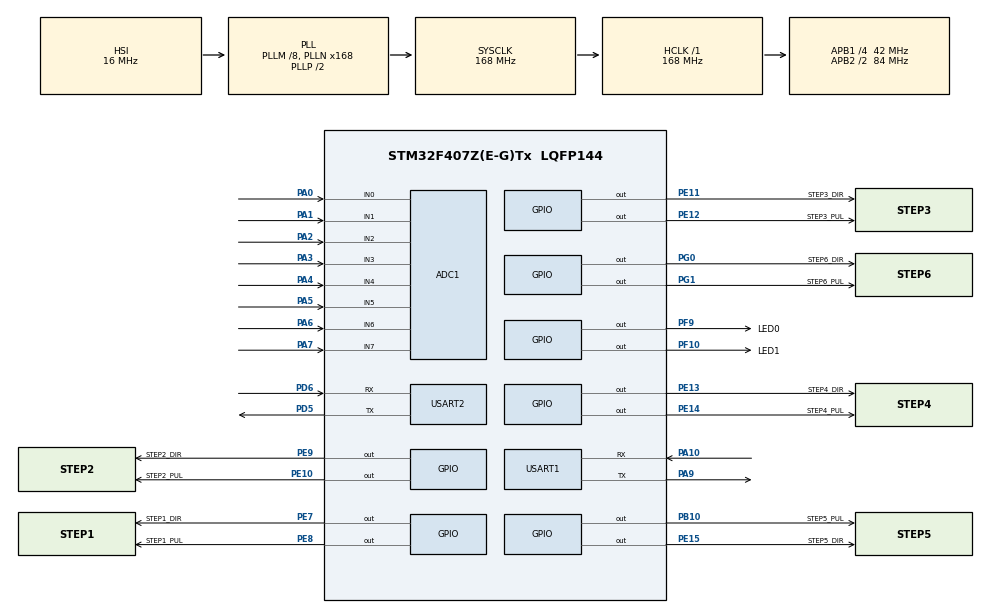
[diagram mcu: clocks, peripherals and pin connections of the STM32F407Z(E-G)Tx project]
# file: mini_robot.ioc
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Mcu.Family=STM32F4
Dma.USART2_RX.2.PeriphDataAlignment=DMA_PDATAALIGN_BYTE
PH0-OSC_IN.Signal=RCC_OSC_IN
RCC.CortexFreq_Value=168000000
Dma.USART1_TX.1.MemInc=DMA_MINC_ENABLE
ADC1.ContinuousConvMode=ENABLE
Dma.USART2_TX.3.MemInc=DMA_MINC_ENABLE
PE11.GPIO_Label=STEP3_DIR
SH.ADCx_IN2.0=ADC1_IN2,IN2
ADC1.SamplingTime-6\#ChannelRegularConversion=ADC_SAMPLETIME_56CYCLES
PG0.Signal=GPIO_Output
Dma.USART2_TX.3.Direction=DMA_MEMORY_TO_PERIPH
RCC.SYSCLKSource=RCC_SYSCLKSOURCE_PLLCLK
ProjectManager.StackSize=0x1600
VP_TIM1_VS_no_output1.Mode=Output Compare1 No Output
NVIC.ADC_IRQn=true\:5\:0\:false\:false\:true\:true\:true\:true
ADC1.Channel-5\#ChannelRegularConversion=ADC_CHANNEL_5
ADC1.Channel-3\#ChannelRegularConversion=ADC_CHANNEL_3
RCC.HCLKFreq_Value=168000000
SH.ADCx_IN3.0=ADC1_IN3,IN3
RCC.APB2TimFreq_Value=168000000
Dma.ADC1.0.Direction=DMA_PERIPH_TO_MEMORY
ADC1.Channel-2\#ChannelRegularConversion=ADC_CHANNEL_2
Dma.USART2_RX.2.Priority=DMA_PRIORITY_HIGH
Dma.USART2_RX.2.MemDataAlignment=DMA_MDATAALIGN_BYTE
NVIC.DMA2_Stream0_IRQn=true\:5\:0\:false\:false\:true\:true\:false\:true
Dma.ADC1.0.MemDataAlignment=DMA_MDATAALIGN_HALFWORD
PF10.GPIO_Label=LED1
RCC.AHBFreq_Value=168000000
PH0-OSC_IN.Mode=HSE-External-Oscillator
PD5.Mode=Asynchronous
ADC1.Channel-0\#ChannelRegularConversion=ADC_CHANNEL_0
RCC.HSE_VALUE=8000000
ADC1.ScanConvMode=ENABLE
ADC1.SamplingTime-4\#ChannelRegularConversion=ADC_SAMPLETIME_56CYCLES
ADC1.Channel-6\#ChannelRegularConversion=ADC_CHANNEL_6
ADC1.Rank-2\#ChannelRegularConversion=3
PE13.Signal=GPIO_Output
PC14-OSC32_IN.Mode=LSE-External-Oscillator
PE9.Signal=GPIO_Output
PA14.Mode=Serial_Wire
FREERTOS.HEAP_NUMBER=3
Dma.ADC1.0.PeriphInc=DMA_PINC_DISABLE
SH.ADCx_IN0.0=ADC1_IN0,IN0
VP_FREERTOS_VS_CMSIS_V1.Mode=CMSIS_V1
PE10.Signal=GPIO_Output
ADC1.SamplingTime-0\#ChannelRegularConversion=ADC_SAMPLETIME_56CYCLES
FREERTOS.configTOTAL_HEAP_SIZE=25360
Dma.USART1_TX.1.PeriphDataAlignment=DMA_PDATAALIGN_BYTE
PH1-OSC_OUT.Mode=HSE-External-Oscillator
Mcu.Package=LQFP144
PA6.Signal=ADCx_IN6
NVIC.DMA2_Stream7_IRQn=true\:5\:0\:false\:false\:true\:true\:false\:true
USART2.VirtualMode=VM_ASYNC
PA10.Signal=USART1_RX
PE12.GPIO_Label=STEP3_PUL
PG0.GPIO_Label=STEP6_DIR
Dma.USART2_RX.2.Direction=DMA_PERIPH_TO_MEMORY
RCC.APB2CLKDivider=RCC_HCLK_DIV2
SH.ADCx_IN1.0=ADC1_IN1,IN1
Dma.Request2=USART2_RX
Dma.Request1=USART1_TX
RCC.APB1TimFreq_Value=84000000
Dma.Request3=USART2_TX
Dma.ADC1.0.FIFOMode=DMA_FIFOMODE_DISABLE
Dma.USART1_TX.1.Priority=DMA_PRIORITY_LOW
PE7.Signal=GPIO_Output
NVIC.USART1_IRQn=true\:5\:0\:false\:false\:true\:true\:true\:true
PD6.Signal=USART2_RX
PE10.GPIO_Label=STEP2_PUL
ADC1.Rank-6\#ChannelRegularConversion=7
Dma.Request0=ADC1
NVIC.DMA1_Stream6_IRQn=true\:5\:0\:false\:false\:true\:true\:false\:true
ADC1.Rank-4\#ChannelRegularConversion=5
PA3.Signal=ADCx_IN3
Dma.USART1_TX.1.Direction=DMA_MEMORY_TO_PERIPH
PE14.GPIO_ModeDefaultOutputPP=GPIO_MODE_OUTPUT_OD
PC15-OSC32_OUT.Mode=LSE-External-Oscillator
Dma.USART2_TX.3.MemDataAlignment=DMA_MDATAALIGN_BYTE
Dma.USART1_TX.1.Instance=DMA2_Stream7
Dma.ADC1.0.Instance=DMA2_Stream0
FREERTOS.Tasks01=defaultTask,0,128,StartDefaultTask,Default,NULL,Dynamic,NULL,NULL;LedTask,-2,128,StartLedTask,Default,NULL,Dynamic,NULL,NULL;SendTask,0,512,StartSendTask,Default,NULL,Dynamic,NULL,NULL;RobotTask,2,256,StartRobotTask,Default,NULL,Dynamic,NULL,NULL;DemoTask,0,128,StartDemoTask,Default,NULL,Dynamic,NULL,NULL;TestTask,1,128,StartTestTask,Default,NULL,Dynamic,NULL,NULL;ModbusTask,0,512,StartModbusTask,Default,NULL,Dynamic,NULL,NULL
ADC1.Rank-0\#ChannelRegularConversion=1
ADC1.Channel-4\#ChannelRegularConversion=ADC_CHANNEL_4
PA10.Mode=Asynchronous
Dma.USART2_TX.3.Instance=DMA1_Stream6
SH.ADCx_IN6.0=ADC1_IN6,IN6
PG1.Signal=GPIO_Output
TIM1.Channel-Output\ Compare1\ No\ Output=TIM_CHANNEL_1
PE14.GPIO_Label=STEP4_PUL
PD5.Signal=USART2_TX
Dma.USART2_TX.3.PeriphInc=DMA_PINC_DISABLE
RCC.APB1CLKDivider=RCC_HCLK_DIV4
PC14-OSC32_IN.Signal=RCC_OSC32_IN
PD6.Mode=Asynchronous
NVIC.USART2_IRQn=true\:5\:0\:false\:false\:true\:true\:true\:true
ADC1.SamplingTime-2\#ChannelRegularConversion=ADC_SAMPLETIME_56CYCLES
Dma.USART2_RX.2.Mode=DMA_CIRCULAR
PA0-WKUP.Signal=ADCx_IN0
ADC1.Channel-7\#ChannelRegularConversion=ADC_CHANNEL_7
PA13.Signal=SYS_JTMS-SWDIO
Dma.ADC1.0.PeriphDataAlignment=DMA_PDATAALIGN_HALFWORD
PA9.Mode=Asynchronous
PE15.GPIO_Label=STEP5_DIR
Dma.USART2_RX.2.MemInc=DMA_MINC_ENABLE
ProjectManager.TargetToolchain=STM32CubeIDE
PB10.GPIO_Label=STEP5_PUL
NVIC.DMA1_Stream5_IRQn=true\:5\:0\:false\:false\:true\:true\:false\:true
SH.ADCx_IN7.0=ADC1_IN7,IN7
Dma.ADC1.0.Mode=DMA_CIRCULAR
PE8.GPIO_Label=STEP1_PUL
Dma.ADC1.0.Priority=DMA_PRIORITY_HIGH
PA9.Signal=USART1_TX
ADC1.Channel-1\#ChannelRegularConversion=ADC_CHANNEL_1
Dma.USART2_TX.3.PeriphDataAlignment=DMA_PDATAALIGN_BYTE
Dma.USART1_TX.1.FIFOMode=DMA_FIFOMODE_DISABLE
PF9.GPIO_Label=LED0
PE11.Signal=GPIO_Output
PC15-OSC32_OUT.Signal=RCC_OSC32_OUT
PE9.GPIO_Label=STEP2_DIR
PA1.Signal=ADCx_IN1
PB10.Signal=GPIO_Output
PA5.Signal=ADCx_IN5
Dma.USART2_TX.3.FIFOMode=DMA_FIFOMODE_DISABLE
Dma.USART1_TX.1.MemDataAlignment=DMA_MDATAALIGN_BYTE
board=custom
RCC.VCOOutputFreq_Value=336000000
PG1.GPIO_Label=STEP6_PUL
Dma.USART2_RX.2.PeriphInc=DMA_PINC_DISABLE
RCC.APB2Freq_Value=84000000
PE14.Signal=GPIO_Output
PE15.Signal=GPIO_Output
PE8.Signal=GPIO_Output
PF10.Signal=GPIO_Output
Dma.USART2_TX.3.Mode=DMA_NORMAL
PH1-OSC_OUT.Signal=RCC_OSC_OUT
SH.ADCx_IN4.0=ADC1_IN4,IN4
ADC1.DMAContinuousRequests=ENABLE
ADC1.NbrOfConversion=8
PA13.Mode=Serial_Wire
Mcu.Name=STM32F407Z(E-G)Tx
PE7.GPIO_Label=STEP1_DIR
PE12.Signal=GPIO_Output
PA2.Signal=ADCx_IN2
NVIC.TIM1_CC_IRQn=true\:5\:0\:false\:false\:true\:true\:true\:true
RCC.48MHZClocksFreq_Value=84000000
PA4.Signal=ADCx_IN4
ADC1.SamplingTime-1\#ChannelRegularConversion=ADC_SAMPLETIME_56CYCLES
RCC.SYSCLKFreq_VALUE=168000000
ADC1.master=1
PE13.GPIO_Label=STEP4_DIR
ADC1.Rank-3\#ChannelRegularConversion=4
ADC1.SamplingTime-3\#ChannelRegularConversion=ADC_SAMPLETIME_56CYCLES
Dma.USART2_RX.2.Instance=DMA1_Stream5
PE13.GPIO_ModeDefaultOutputPP=GPIO_MODE_OUTPUT_OD
Dma.USART1_TX.1.Mode=DMA_NORMAL
USART1.VirtualMode=VM_ASYNC
ADC1.Rank-1\#ChannelRegularConversion=2
PA14.Signal=SYS_JTCK-SWCLK
Dma.ADC1.0.MemInc=DMA_MINC_ENABLE
ProjectManager.HeapSize=0x800
Dma.USART1_TX.1.PeriphInc=DMA_PINC_DISABLE
ADC1.SamplingTime-5\#ChannelRegularConversion=ADC_SAMPLETIME_56CYCLES
PF9.Signal=GPIO_Output
RCC.HSI_VALUE=16000000
Dma.USART2_TX.3.Priority=DMA_PRIORITY_HIGH
SH.ADCx_IN5.0=ADC1_IN5,IN5
ADC1.Rank-7\#ChannelRegularConversion=8
NVIC.PriorityGroup=NVIC_PRIORITYGROUP_4
ADC1.NbrOfConversionFlag=1
RCC.PLLM=8
RCC.PLLN=168
Dma.USART2_RX.2.FIFOMode=DMA_FIFOMODE_DISABLE
ADC1.SamplingTime-7\#ChannelRegularConversion=ADC_SAMPLETIME_56CYCLES
RCC.APB1Freq_Value=42000000
ADC1.Rank-5\#ChannelRegularConversion=6
PA7.Signal=ADCx_IN7

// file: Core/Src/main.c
/* USER CODE BEGIN Header */
/**
  ******************************************************************************
  * @file           : main.c
  * @brief          : Main program body
  ******************************************************************************
  * @attention
  *
  * <h2><center>&copy; Copyright (c) 2021 STMicroelectronics.
  * All rights reserved.</center></h2>
  *
  * This software component is licensed by ST under BSD 3-Clause license,
  * the "License"; You may not use this file except in compliance with the
  * License. You may obtain a copy of the License at:
  *                        opensource.org/licenses/BSD-3-Clause
  *
  ******************************************************************************
  */
/* USER CODE END Header */
#include "main.h"
#include "cmsis_os.h"
#include "adc.h"
#include "dma.h"
#include "tim.h"
#include "usart.h"
#include "gpio.h"

/* USER CODE BEGIN Includes */
#include "math.h"
/* USER CODE END Includes */

void SystemClock_Config(void);
void MX_FREERTOS_Init(void);

int main(void)
{

  /* MCU Configuration--------------------------------------------------------*/

  /* Reset of all peripherals, Initializes the Flash interface and the Systick. */
  HAL_Init();

  /* Configure the system clock */
  SystemClock_Config();

  /* Initialize all configured peripherals */
  MX_GPIO_Init();
  MX_DMA_Init();
  MX_ADC1_Init();
  MX_USART1_UART_Init();
  MX_USART2_UART_Init();
  MX_TIM1_Init();
  /* USER CODE BEGIN 2 */
  HAL_ADC_Start_DMA(&hadc1, (uint32_t *)adc_data, 8);
  HAL_UART_Receive_DMA(&huart2, rx_data, rx_bufSize);
  HAL_TIM_Base_Start_IT(&htim1);
  HAL_TIM_OC_Start_IT(&htim1,TIM_CHANNEL_1);

  /* USER CODE END 2 */

  /* Call init function for freertos objects (in freertos.c) */
  MX_FREERTOS_Init();
  /* Start scheduler */
  osKernelStart();

  /* We should never get here as control is now taken by the scheduler */
  /* Infinite loop */
  while (1)
  {

  }
}

void SystemClock_Config(void)
{
  RCC_OscInitTypeDef RCC_OscInitStruct = {0};
  RCC_ClkInitTypeDef RCC_ClkInitStruct = {0};

  /** Configure the main internal regulator output voltage
  */
  __HAL_RCC_PWR_CLK_ENABLE();
  __HAL_PWR_VOLTAGESCALING_CONFIG(PWR_REGULATOR_VOLTAGE_SCALE1);
  /** Initializes the RCC Oscillators according to the specified parameters
  * in the RCC_OscInitTypeDef structure.
  */
  RCC_OscInitStruct.OscillatorType = RCC_OSCILLATORTYPE_HSI;
  RCC_OscInitStruct.HSIState = RCC_HSI_ON;
  RCC_OscInitStruct.HSICalibrationValue = RCC_HSICALIBRATION_DEFAULT;
  RCC_OscInitStruct.PLL.PLLState = RCC_PLL_ON;
  RCC_OscInitStruct.PLL.PLLSource = RCC_PLLSOURCE_HSI;
  RCC_OscInitStruct.PLL.PLLM = 8;
  RCC_OscInitStruct.PLL.PLLN = 168;
  RCC_OscInitStruct.PLL.PLLP = RCC_PLLP_DIV2;
  RCC_OscInitStruct.PLL.PLLQ = 4;
  if (HAL_RCC_OscConfig(&RCC_OscInitStruct) != HAL_OK)
  {
    Error_Handler();
  }
  /** Initializes the CPU, AHB and APB buses clocks
  */
  RCC_ClkInitStruct.ClockType = RCC_CLOCKTYPE_HCLK|RCC_CLOCKTYPE_SYSCLK
                              |RCC_CLOCKTYPE_PCLK1|RCC_CLOCKTYPE_PCLK2;
  RCC_ClkInitStruct.SYSCLKSource = RCC_SYSCLKSOURCE_PLLCLK;
  RCC_ClkInitStruct.AHBCLKDivider = RCC_SYSCLK_DIV1;
  RCC_ClkInitStruct.APB1CLKDivider = RCC_HCLK_DIV4;
  RCC_ClkInitStruct.APB2CLKDivider = RCC_HCLK_DIV2;

  if (HAL_RCC_ClockConfig(&RCC_ClkInitStruct, FLASH_LATENCY_5) != HAL_OK)
  {
    Error_Handler();
  }
}

/* USER CODE BEGIN 4 */

int get_max(int *arr){
	int max=0;
	for(int i=3;i<9;i++){
		if(arr[i]>max)max=arr[i];
	}
	return max;
}
int max(int a, int b){
	if(a>b)return a;
	else return b;
}

int max_pulse=0;
int step1_err=0;
int step2_err=0;
int step3_err=0;
int step4_err=0;
int step5_err=0;
int step6_err=0;

int step1_foc=0;
int step2_foc=0;
int step3_foc=0;
int step4_foc=0;
int step5_foc=0;
int step6_foc=0;

float step1_scale=0;
float step2_scale=0;
float step3_scale=0;
float step4_scale=0;
float step5_scale=0;
float step6_scale=0;

char step1_flag=0;
char step2_flag=0;
char step3_flag=0;
char step4_flag=0;
char step5_flag=0;
char step6_flag=0;

long cur_num = 0;
int acc_pulse = 0;
int instruct_speed = 0;
char step4_is_run = 0;

double x=0,y=0,z=0,a1=0,a2=0,a3=0;
double L1=2520,L2=1410,L3=0;

double ik_a1=0,ik_a2=0,ik_a3=0,ik_a4=0,ik_a5=0,ik_a6=0;
double new_x=0,new_y=0,new_z=0,ik_x,ik_y,ik_z;
int num =0;
int max_xyz=0;
int last_xyz=0;
char key_flag = 0;
char max_flag = 0;
int start_pul1,start_pul2,start_pul3,start_pul4,start_pul5,start_pul6;
void HAL_TIM_OC_DelayElapsedCallback(TIM_HandleTypeDef *htim)
{
	if(htim==&htim1){

		HAL_GPIO_WritePin(STEP1_PUL_GPIO_Port,STEP1_PUL_Pin,GPIO_PIN_SET);
		HAL_GPIO_WritePin(STEP2_PUL_GPIO_Port,STEP2_PUL_Pin,GPIO_PIN_SET);
		HAL_GPIO_WritePin(STEP3_PUL_GPIO_Port,STEP3_PUL_Pin,GPIO_PIN_SET);
		HAL_GPIO_WritePin(STEP4_PUL_GPIO_Port,STEP4_PUL_Pin,GPIO_PIN_RESET);
		HAL_GPIO_WritePin(STEP5_PUL_GPIO_Port,STEP5_PUL_Pin,GPIO_PIN_SET);
		HAL_GPIO_WritePin(STEP6_PUL_GPIO_Port,STEP6_PUL_Pin,GPIO_PIN_SET);

//		num++;
//		if(num%10==0)
//		{
//			L3 = sqrt(-2.0*L1*L2*cos((cur_pulse3*0.0113924+180)/57.2958)+L1*L1+L2*L2);
//			float cc = cur_pulse2*0.0067164/57.2958 - acos((L1*L1+L3*L3-L2*L2)/(2.0*L1*L3));
//			z = L3*sin(cc);
//			instruct[4][0] = (int)z;
//			x = cos(cur_pulse1*0.006338/57.2958)*L3*cos(cc);
//			y = sin(cur_pulse1*0.006338/57.2958)*L3*cos(cc);
//			instruct[4][1] = (int)x;
//			instruct[4][2] = (int)y;
//		}

		if(!is_start){
			if(foc_cut[0]>100){
				step1_foc++;
				if(step1_foc>(10000/(foc_cut[0]))){
					step1_foc=0;
					HAL_GPIO_WritePin(STEP1_DIR_GPIO_Port,STEP1_DIR_Pin,GPIO_PIN_RESET);
					HAL_GPIO_WritePin(STEP1_PUL_GPIO_Port,STEP1_PUL_Pin,GPIO_PIN_RESET);
					cur_pulse1++;
				}
			}

			if(foc_cut[0]<-100){
				step1_foc--;
				if(step1_foc<(10000/(foc_cut[0]))){
					step1_foc=0;
					HAL_GPIO_WritePin(STEP1_DIR_GPIO_Port,STEP1_DIR_Pin,GPIO_PIN_SET);
					HAL_GPIO_WritePin(STEP1_PUL_GPIO_Port,STEP1_PUL_Pin,GPIO_PIN_RESET);
					cur_pulse1--;
				}
			}

			if(foc_cut[1]>100){
				step2_foc++;
				if(step2_foc>(20000/(foc_cut[1]))){
					step2_foc=0;
					HAL_GPIO_WritePin(STEP2_DIR_GPIO_Port,STEP2_DIR_Pin,GPIO_PIN_RESET);
					HAL_GPIO_WritePin(STEP2_PUL_GPIO_Port,STEP2_PUL_Pin,GPIO_PIN_RESET);
					cur_pulse2++;
				}
			}

			if(foc_cut[1]<-100){
				step2_foc--;
				if(step2_foc<(20000/(foc_cut[1]))){
					step2_foc=0;
					HAL_GPIO_WritePin(STEP2_DIR_GPIO_Port,STEP2_DIR_Pin,GPIO_PIN_SET);
					HAL_GPIO_WritePin(STEP2_PUL_GPIO_Port,STEP2_PUL_Pin,GPIO_PIN_RESET);
					cur_pulse2--;
				}
			}

			if(foc_cut[2]>100){
				step3_foc++;
				if(step3_foc>(10000/(foc_cut[2]))){
					step3_foc=0;
					HAL_GPIO_WritePin(STEP3_DIR_GPIO_Port,STEP3_DIR_Pin,GPIO_PIN_SET);
					HAL_GPIO_WritePin(STEP3_PUL_GPIO_Port,STEP3_PUL_Pin,GPIO_PIN_RESET);
					cur_pulse3++;
				}
			}

			if(foc_cut[2]<-100){
				step3_foc--;
				if(step3_foc<(10000/(foc_cut[2]))){
					step3_foc=0;
					HAL_GPIO_WritePin(STEP3_DIR_GPIO_Port,STEP3_DIR_Pin,GPIO_PIN_RESET);
					HAL_GPIO_WritePin(STEP3_PUL_GPIO_Port,STEP3_PUL_Pin,GPIO_PIN_RESET);
					cur_pulse3--;
				}
			}

			if(foc_cut[3]>100){
				step4_foc++;
				if(step4_foc>(10000/(foc_cut[3]))){
					step4_foc=0;
					HAL_GPIO_WritePin(STEP4_DIR_GPIO_Port,STEP4_DIR_Pin,GPIO_PIN_RESET);
					HAL_GPIO_WritePin(STEP4_PUL_GPIO_Port,STEP4_PUL_Pin,GPIO_PIN_SET);
					cur_pulse4++;
					HAL_GPIO_WritePin(STEP5_DIR_GPIO_Port,STEP5_DIR_Pin,GPIO_PIN_SET);
					HAL_GPIO_WritePin(STEP5_PUL_GPIO_Port,STEP5_PUL_Pin,GPIO_PIN_RESET);

				}
			}

			if(foc_cut[3]<-100){
				step4_foc--;
				if(step4_foc<(10000/(foc_cut[3]))){
					step4_foc=0;
					HAL_GPIO_WritePin(STEP4_DIR_GPIO_Port,STEP4_DIR_Pin,GPIO_PIN_SET);
					HAL_GPIO_WritePin(STEP4_PUL_GPIO_Port,STEP4_PUL_Pin,GPIO_PIN_SET);
					cur_pulse4--;
					HAL_GPIO_WritePin(STEP5_DIR_GPIO_Port,STEP5_DIR_Pin,GPIO_PIN_RESET);
					HAL_GPIO_WritePin(STEP5_PUL_GPIO_Port,STEP5_PUL_Pin,GPIO_PIN_RESET);
				}
			}

			if(foc_cut[4]>100){
				step5_foc++;
				if(step5_foc>(10000/(foc_cut[4]))){
					step5_foc=0;
					HAL_GPIO_WritePin(STEP5_DIR_GPIO_Port,STEP5_DIR_Pin,GPIO_PIN_RESET);
					HAL_GPIO_WritePin(STEP5_PUL_GPIO_Port,STEP5_PUL_Pin,GPIO_PIN_RESET);
					cur_pulse5++;
				}
			}

			if(foc_cut[4]<-100){
				step5_foc--;
				if(step5_foc<(10000/(foc_cut[4]))){
					step5_foc=0;
					HAL_GPIO_WritePin(STEP5_DIR_GPIO_Port,STEP5_DIR_Pin,GPIO_PIN_SET);
					HAL_GPIO_WritePin(STEP5_PUL_GPIO_Port,STEP5_PUL_Pin,GPIO_PIN_RESET);
					cur_pulse5--;
				}
			}

			if(foc_cut[5]>100){
				step6_foc++;
				if(step6_foc>(5000/(foc_cut[5]))){
					step6_foc=0;
					HAL_GPIO_WritePin(STEP6_DIR_GPIO_Port,STEP6_DIR_Pin,GPIO_PIN_SET);
					HAL_GPIO_WritePin(STEP6_PUL_GPIO_Port,STEP6_PUL_Pin,GPIO_PIN_RESET);
					cur_pulse6=cur_pulse6+6;
				}
			}

			if(foc_cut[5]<-100){
				step6_foc--;
				if(step6_foc<(5000/(foc_cut[5]))){
					step6_foc=0;
					HAL_GPIO_WritePin(STEP6_DIR_GPIO_Port,STEP6_DIR_Pin,GPIO_PIN_RESET);
					HAL_GPIO_WritePin(STEP6_PUL_GPIO_Port,STEP6_PUL_Pin,GPIO_PIN_RESET);
					cur_pulse6=cur_pulse6-6;
				}
			}

		}

		if((is_start||is_single_run))
		{
			step_time++;
			instruct[0][10] = (int)step_time/100.0;
//			if(max_pulse==(int)step)
			if(((abs(cur_pulse1-instruct[instruct_step][4])<10)&&
				 (abs(cur_pulse2-instruct[instruct_step][5])<10)&&
				 (abs(cur_pulse3-instruct[instruct_step][6])<10))||
				 (key_flag==0&&is_single_run))
			{
				if(!is_single_run&&(int)(step_time/100.0)>instruct[instruct_step][10])
				{
					step_time = 0;
					instruct_step++;instruct[2][2]++;
					key_flag = 0;
				}
				step=0;
				if((instruct[2][2]+10)>instruct[2][1])
				{
					instruct[2][2] = 0;
					instruct_step=10;

					if((instruct[3][4]*65536+instruct[3][3])>=(instruct[3][2]*65536+instruct[3][1]))
					{
						is_start = 0;
						instruct[3][0]=0;
					}
					else{
						cur_num = instruct[3][4]*65536+instruct[3][3];
						cur_num++;
						instruct[3][4] = cur_num>>16;
						instruct[3][3] = cur_num&0xffff;

					}
				}

				max_pulse = max(abs(instruct[instruct_step][4]-cur_pulse1),abs(instruct[instruct_step][5]-cur_pulse2));
				max_pulse = max(max_pulse,abs(instruct[instruct_step][6]-cur_pulse3));
				max_pulse = max(max_pulse,abs(instruct[instruct_step][7]-cur_pulse4));
				max_pulse = max(max_pulse,abs(instruct[instruct_step][8]-cur_pulse5));
				max_pulse = max(max_pulse,abs(instruct[instruct_step][9]-cur_pulse6));
				step1_scale=abs(instruct[instruct_step][4]-cur_pulse1)/(float)max_pulse;
				step2_scale=abs(instruct[instruct_step][5]-cur_pulse2)/(float)max_pulse;
				step3_scale=abs(instruct[instruct_step][6]-cur_pulse3)/(float)max_pulse;
				step4_scale=abs(instruct[instruct_step][7]-cur_pulse4)/(float)max_pulse;
				step5_scale=abs(instruct[instruct_step][8]-cur_pulse5)/(float)max_pulse;
				step6_scale=abs(instruct[instruct_step][9]-cur_pulse6)/(float)max_pulse;

//				if(     abs(instruct[instruct_step][4]-cur_pulse1)==max_pulse)max_flag = 1;
//				else if(abs(instruct[instruct_step][5]-cur_pulse2)==max_pulse)max_flag = 2;
//				else if(abs(instruct[instruct_step][6]-cur_pulse3)==max_pulse)max_flag = 3;
//				else if(abs(instruct[instruct_step][7]-cur_pulse4)==max_pulse)max_flag = 4;
//				else if(abs(instruct[instruct_step][8]-cur_pulse5)==max_pulse)max_flag = 5;
//				else if(abs(instruct[instruct_step][9]-cur_pulse6)==max_pulse)max_flag = 6;

//				step_speed = 0;
//				instruct_speed = (int)instruct[instruct_step][2]*instruct[3][5]/100.0;
			}
			instruct_speed = (int)instruct[instruct_step][2]*instruct[3][5]/100.0;
			if(instruct[instruct_step][0]==0)
			{

				if((key_flag==0&&is_single_run)||(key_flag==0&&is_start))
				{
					step_speed = 0;
					step=0;
					max_pulse = max(abs(instruct[instruct_step][4]-cur_pulse1),abs(instruct[instruct_step][5]-cur_pulse2));
					max_pulse = max(max_pulse,abs(instruct[instruct_step][6]-cur_pulse3));
					max_pulse = max(max_pulse,abs(instruct[instruct_step][7]-cur_pulse4));
					max_pulse = max(max_pulse,abs(instruct[instruct_step][8]-cur_pulse5));
					max_pulse = max(max_pulse,abs(instruct[instruct_step][9]-cur_pulse6));
					step1_scale=abs(instruct[instruct_step][4]-cur_pulse1)/(float)max_pulse;
					step2_scale=abs(instruct[instruct_step][5]-cur_pulse2)/(float)max_pulse;
					step3_scale=abs(instruct[instruct_step][6]-cur_pulse3)/(float)max_pulse;
					step4_scale=abs(instruct[instruct_step][7]-cur_pulse4)/(float)max_pulse;
					step5_scale=abs(instruct[instruct_step][8]-cur_pulse5)/(float)max_pulse;
					step6_scale=abs(instruct[instruct_step][9]-cur_pulse6)/(float)max_pulse;

					key_flag=1;

				}
				instruct[0][2] = (int)step_speed;
				instruct[0][3] = (int)((step_acc)*((instruct_speed)*1.1-step_speed)/instruct_speed);
				if((int)step_speed<(instruct_speed)&&((float)step<((float)max_pulse/2.0)))
				{
					step_acc = instruct[instruct_step][3];
	//				step_speed=step_speed+(step_acc/1000.0)*(1-sin(((instruct[instruct_step][2])-step_speed)/162.4));
					step_speed=step_speed+(step_acc/1000.0)*((instruct_speed)*1.1-step_speed)/instruct_speed;
					acc_pulse = (int)step;
				}

				if((int)step_speed>(instruct_speed)||(((int)step)>(max_pulse-acc_pulse)&&(int)step_speed>2))
				{
					step_acc = instruct[instruct_step][3];
	//				step_speed=step_speed-(step_acc/1000.0)*(1-sin((step_speed-(instruct[instruct_step][2]))/162.4));
					step_speed=step_speed-(step_acc/1000.0)*((instruct_speed)*1.1-step_speed)/instruct_speed;
				}

				step=step+step_speed/255.0;

				if((step1_err!=(int)(step*step1_scale))&&(abs(foc_cut[0])<800)){
					step1_err=(int)(step*step1_scale);
					if(cur_pulse1<instruct[instruct_step][4]){
						HAL_GPIO_WritePin(STEP1_DIR_GPIO_Port,STEP1_DIR_Pin,GPIO_PIN_RESET);
						HAL_GPIO_WritePin(STEP1_PUL_GPIO_Port,STEP1_PUL_Pin,GPIO_PIN_RESET);
						cur_pulse1++;

					}
					else if (cur_pulse1>instruct[instruct_step][4]){
						HAL_GPIO_WritePin(STEP1_DIR_GPIO_Port,STEP1_DIR_Pin,GPIO_PIN_SET);
						HAL_GPIO_WritePin(STEP1_PUL_GPIO_Port,STEP1_PUL_Pin,GPIO_PIN_RESET);
						cur_pulse1--;

					}

				}

				if((step2_err!=(int)(step*step2_scale))&&(abs(foc_cut[1])<800)){
					step2_err=(int)(step*step2_scale);
					if(cur_pulse2<instruct[instruct_step][5]){
						HAL_GPIO_WritePin(STEP2_DIR_GPIO_Port,STEP2_DIR_Pin,GPIO_PIN_RESET);
						HAL_GPIO_WritePin(STEP2_PUL_GPIO_Port,STEP2_PUL_Pin,GPIO_PIN_RESET);
						cur_pulse2++;

					}
					else if (cur_pulse2>instruct[instruct_step][5]){
						HAL_GPIO_WritePin(STEP2_DIR_GPIO_Port,STEP2_DIR_Pin,GPIO_PIN_SET);
						HAL_GPIO_WritePin(STEP2_PUL_GPIO_Port,STEP2_PUL_Pin,GPIO_PIN_RESET);
						cur_pulse2--;

					}

				}

				if((step3_err!=(int)(step*step3_scale))&&(abs(foc_cut[2])<800)){
					step3_err=(int)(step*step3_scale);
					if(cur_pulse3<instruct[instruct_step][6]){
						HAL_GPIO_WritePin(STEP3_DIR_GPIO_Port,STEP3_DIR_Pin,GPIO_PIN_SET);
						HAL_GPIO_WritePin(STEP3_PUL_GPIO_Port,STEP3_PUL_Pin,GPIO_PIN_RESET);
						cur_pulse3++;

					}
					else if (cur_pulse3>instruct[instruct_step][6]){
						HAL_GPIO_WritePin(STEP3_DIR_GPIO_Port,STEP3_DIR_Pin,GPIO_PIN_RESET);
						HAL_GPIO_WritePin(STEP3_PUL_GPIO_Port,STEP3_PUL_Pin,GPIO_PIN_RESET);
						cur_pulse3--;

					}

				}

				if((step4_err!=(int)(step*step4_scale))&&(abs(foc_cut[3])<800)){

					step4_err=(int)(step*step4_scale);
					if(cur_pulse4<instruct[instruct_step][7]){
						step4_is_run = 1;
						HAL_GPIO_WritePin(STEP4_DIR_GPIO_Port,STEP4_DIR_Pin,GPIO_PIN_RESET);
						HAL_GPIO_WritePin(STEP4_PUL_GPIO_Port,STEP4_PUL_Pin,GPIO_PIN_SET);
						cur_pulse4++;
						HAL_GPIO_WritePin(STEP5_DIR_GPIO_Port,STEP5_DIR_Pin,GPIO_PIN_SET);
						HAL_GPIO_WritePin(STEP5_PUL_GPIO_Port,STEP5_PUL_Pin,GPIO_PIN_RESET);

					}
					else if (cur_pulse4>instruct[instruct_step][7]){
						step4_is_run = 1;
						HAL_GPIO_WritePin(STEP4_DIR_GPIO_Port,STEP4_DIR_Pin,GPIO_PIN_SET);
						HAL_GPIO_WritePin(STEP4_PUL_GPIO_Port,STEP4_PUL_Pin,GPIO_PIN_SET);
						cur_pulse4--;
						HAL_GPIO_WritePin(STEP5_DIR_GPIO_Port,STEP5_DIR_Pin,GPIO_PIN_RESET);
						HAL_GPIO_WritePin(STEP5_PUL_GPIO_Port,STEP5_PUL_Pin,GPIO_PIN_RESET);

					}

				}else step4_is_run=0;

				if((step5_err!=(int)(step*step5_scale))&&(step4_is_run==0)&&(abs(foc_cut[4])<800)){
					step5_err=(int)(step*step5_scale);
					if(cur_pulse5<instruct[instruct_step][8]){
						HAL_GPIO_WritePin(STEP5_DIR_GPIO_Port,STEP5_DIR_Pin,GPIO_PIN_RESET);
						HAL_GPIO_WritePin(STEP5_PUL_GPIO_Port,STEP5_PUL_Pin,GPIO_PIN_RESET);
						cur_pulse5++;
					}
					else if (cur_pulse5>instruct[instruct_step][8]){
						HAL_GPIO_WritePin(STEP5_DIR_GPIO_Port,STEP5_DIR_Pin,GPIO_PIN_SET);
						HAL_GPIO_WritePin(STEP5_PUL_GPIO_Port,STEP5_PUL_Pin,GPIO_PIN_RESET);
						cur_pulse5--;
					}

				}

				if((step6_err!=(int)(step*step6_scale))&&(abs(foc_cut[5])<800)){
					step6_err=(int)(step*step6_scale);
					if(cur_pulse6<instruct[instruct_step][9]){
						HAL_GPIO_WritePin(STEP6_DIR_GPIO_Port,STEP6_DIR_Pin,GPIO_PIN_SET);
						HAL_GPIO_WritePin(STEP6_PUL_GPIO_Port,STEP6_PUL_Pin,GPIO_PIN_RESET);
						cur_pulse6=cur_pulse6+6;
					}
					else if (cur_pulse6>instruct[instruct_step][9]){
						HAL_GPIO_WritePin(STEP6_DIR_GPIO_Port,STEP6_DIR_Pin,GPIO_PIN_RESET);
						HAL_GPIO_WritePin(STEP6_PUL_GPIO_Port,STEP6_PUL_Pin,GPIO_PIN_RESET);
						cur_pulse6=cur_pulse6-6;
					}
				}

			}

			if(instruct[instruct_step][0]==1)
			{

				if((key_flag==0&&is_single_run)||(key_flag==0&&is_start))
				{
					key_flag = 1;
					start_pul1 = cur_pulse1;
					start_pul2 = cur_pulse2;
					start_pul3 = cur_pulse3;
					start_pul4 = cur_pulse4;
					start_pul5 = cur_pulse5;
					start_pul6 = cur_pulse6;

					L3 = sqrt(-2.0*L1*L2*cos((cur_pulse3*0.0113924+180)/57.2958)+L1*L1+L2*L2);
					float cc = cur_pulse2*0.0067164/57.2958 - acos((L1*L1+L3*L3-L2*L2)/(2.0*L1*L3));
					z = L3*sin(cc);
					x = cos(cur_pulse1*0.006338/57.2958)*L3*cos(cc);
					y = sin(cur_pulse1*0.006338/57.2958)*L3*cos(cc);
					new_x = x;
					new_y = y;
					new_z = z;

					double ik_L3 = sqrt(-2.0*L1*L2*cos((instruct[instruct_step][6]*0.0113924+180)/57.2958)+L1*L1+L2*L2);
					double ccc = instruct[instruct_step][5]*0.0067164/57.2958 - acos((L1*L1+ik_L3*ik_L3-L2*L2)/(2.0*L1*ik_L3));
					ik_z = ik_L3*sin(ccc);
					ik_x = cos(instruct[instruct_step][4]*0.006338/57.2958)*ik_L3*cos(ccc);
					ik_y = sin(instruct[instruct_step][4]*0.006338/57.2958)*ik_L3*cos(ccc);
					max_xyz = max(abs((int)ik_z-(int)z),abs((int)ik_y-(int)y));
					max_xyz = max(max_xyz,abs((int)ik_x-(int)x));
					if(max_xyz>3)
					{
						new_z = new_z+(ik_z-z)*2.0/(float)max_xyz;
						new_x = new_x+(ik_x-x)*2.0/(float)max_xyz;
						new_y = new_y+(ik_y-y)*2.0/(float)max_xyz;
						instruct[4][0] = (int)ik_z;
						instruct[4][1] = (int)ik_x;
						instruct[4][2] = (int)ik_y;

						instruct[4][8] = (int)new_z;
						instruct[4][9] = (int)new_x;
						instruct[4][10] = (int)new_y;

						double new_L3 = sqrt(new_z*new_z+new_x*new_x+new_y*new_y);
						ik_a1 = atan2(new_y,new_x)*57.2958/0.006338;
						ik_a2 = (atan2(new_z,sqrt(new_x*new_x+new_y*new_y))+acos((L1*L1+new_L3*new_L3-L2*L2)/(2*L1*new_L3)))*57.2958/0.0067164;
						ik_a3 = acos((L1*L1-new_L3*new_L3+L2*L2)/(2*L1*L2))*57.2958/0.0113924;
						ik_a4 = -(-90.0/0.0156673 + (atan2(sqrt(new_x*new_x+new_y*new_y),new_z)+
								acos((L2*L2+new_L3*new_L3-L1*L1)/(2*L2*new_L3)))*57.2958/0.0156673)*4.0/90.0;

						instruct[4][3] = (int)(ik_a1*0.006338);
						instruct[4][4] = (int)(ik_a2*0.0067164);
						instruct[4][5] = (int)(ik_a3*0.0113924);
						instruct[4][6] = (int)(ik_a4*0.0156673);

						max_pulse = max(abs((int)ik_a1-cur_pulse1),abs((int)ik_a2-cur_pulse2));
						max_pulse = max(max_pulse,abs((int)(ik_a3-180.0/0.0113924)-cur_pulse3));
	//					max_pulse = max(max_pulse,abs(instruct[instruct_step][7]-cur_pulse4));
	//					max_pulse = max(max_pulse,abs(instruct[instruct_step][8]-cur_pulse5));
	//					max_pulse = max(max_pulse,abs(instruct[instruct_step][9]-cur_pulse6));
						step1_scale=abs((int)ik_a1-cur_pulse1)/(float)max_pulse;
						step2_scale=abs((int)ik_a2-cur_pulse2)/(float)max_pulse;
						step3_scale=abs((int)(ik_a3-180.0/0.0113924)-cur_pulse3)/(float)max_pulse;
//						step4_scale=abs((int)(ik_a4)-cur_pulse4)/(float)max_pulse;
	//					step5_scale=abs(instruct[instruct_step][8]-cur_pulse5)/(float)max_pulse;
	//					step6_scale=abs(instruct[instruct_step][9]-cur_pulse6)/(float)max_pulse;

						step_acc = instruct[instruct_step][3];
						float distance_start =(sqrt(
								(cur_pulse1-start_pul1)*(cur_pulse1-start_pul1)+
								(cur_pulse2-start_pul2)*(cur_pulse2-start_pul2)+
								(cur_pulse3-start_pul3)*(cur_pulse3-start_pul3)));
						float distance_all =(sqrt(
								(start_pul1-instruct[instruct_step][4])*(start_pul1-instruct[instruct_step][4])+
								(start_pul2-instruct[instruct_step][5])*(start_pul2-instruct[instruct_step][5])+
								(start_pul3-instruct[instruct_step][6])*(start_pul3-instruct[instruct_step][6])));
						float speed_start = distance_start*sqrt((step_acc/100.0)*instruct[3][5]/5000.0)+3;
						if(((int)(speed_start)<instruct_speed)&&((int)(distance_start)<(int)(distance_all/2.0)))
						{
							step_speed = speed_start;
						}

						float distance_end =(sqrt(
								(cur_pulse1-instruct[instruct_step][4])*(cur_pulse1-instruct[instruct_step][4])+
								(cur_pulse2-instruct[instruct_step][5])*(cur_pulse2-instruct[instruct_step][5])+
								(cur_pulse3-instruct[instruct_step][6])*(cur_pulse3-instruct[instruct_step][6])));
						float speed_end = distance_end*sqrt((step_acc/100.0)*instruct[3][5]/5000.0)+3;
						if(((int)(speed_end)<instruct_speed)&&((int)(distance_end)<(int)(distance_all/2.0)))
						{
							step_speed = speed_end;
						}

					}
				}

				if((abs(((int)ik_a1)-cur_pulse1)<3)&&
					(abs(((int)ik_a2)-cur_pulse2)<3)&&
					(abs(((int)(ik_a3-180/0.0113924))-cur_pulse3)<3)&&
					((abs((int)ik_z-(int)new_z)>1)||
					(abs((int)ik_x-(int)new_x)>1)||
					(abs((int)ik_y-(int)new_y)>1)))
				{

					new_z = new_z+(ik_z-z)*2.0/(float)max_xyz;
					new_x = new_x+(ik_x-x)*2.0/(float)max_xyz;
					new_y = new_y+(ik_y-y)*2.0/(float)max_xyz;
					instruct[4][0] = (int)ik_z;
					instruct[4][1] = (int)ik_x;
					instruct[4][2] = (int)ik_y;

					instruct[4][8] = (int)new_z;
					instruct[4][9] = (int)new_x;
					instruct[4][10] = (int)new_y;

					double new_L3 = sqrt(new_z*new_z+new_x*new_x+new_y*new_y);
					ik_a1 = atan2(new_y,new_x)*57.2958/0.006338;
					ik_a2 = (atan2(new_z,sqrt(new_x*new_x+new_y*new_y))+acos((L1*L1+new_L3*new_L3-L2*L2)/(2.0*L1*new_L3)))*57.2958/0.0067164;
					ik_a3 = acos((L1*L1-new_L3*new_L3+L2*L2)/(2.0*L1*L2))*57.2958/0.0113924;
					ik_a4 = -(-90.0/0.0156673 + (atan2(sqrt(new_x*new_x+new_y*new_y),new_z)+
							acos((L2*L2+new_L3*new_L3-L1*L1)/(2.0*L2*new_L3)))*57.2958/0.0156673)*4.0/90.0;

					instruct[4][3] = (int)(ik_a1*0.006338);
					instruct[4][4] = (int)(ik_a2*0.0067164);
					instruct[4][5] = (int)(ik_a3*0.0113924);
					instruct[4][6] = (int)(ik_a4*0.0156673);
					instruct[4][7] = (int)new_L3;

					max_pulse = max(abs((int)ik_a1-cur_pulse1),abs((int)ik_a2-cur_pulse2));
					max_pulse = max(max_pulse,abs((int)(ik_a3-180.0/0.0113924)-cur_pulse3));
//					max_pulse = max(max_pulse,abs(instruct[instruct_step][7]-cur_pulse4));
//					max_pulse = max(max_pulse,abs(instruct[instruct_step][8]-cur_pulse5));
//					max_pulse = max(max_pulse,abs(instruct[instruct_step][9]-cur_pulse6));
					step1_scale=abs((int)ik_a1-cur_pulse1)/(float)max_pulse;
					step2_scale=abs((int)ik_a2-cur_pulse2)/(float)max_pulse;
					step3_scale=abs((int)(ik_a3-180.0/0.0113924)-cur_pulse3)/(float)max_pulse;
//					step4_scale=abs((int)(ik_a4)-cur_pulse4)/(float)max_pulse;
//					step4_scale=abs(instruct[instruct_step][7]-cur_pulse4)/(float)max_pulse;
//					step5_scale=abs(instruct[instruct_step][8]-cur_pulse5)/(float)max_pulse;
//					step6_scale=abs(instruct[instruct_step][9]-cur_pulse6)/(float)max_pulse;
					step_acc = instruct[instruct_step][3];
					float distance_start =(sqrt(
							(cur_pulse1-start_pul1)*(cur_pulse1-start_pul1)+
							(cur_pulse2-start_pul2)*(cur_pulse2-start_pul2)+
							(cur_pulse3-start_pul3)*(cur_pulse3-start_pul3)));
					float distance_all =(sqrt(
							(start_pul1-instruct[instruct_step][4])*(start_pul1-instruct[instruct_step][4])+
							(start_pul2-instruct[instruct_step][5])*(start_pul2-instruct[instruct_step][5])+
							(start_pul3-instruct[instruct_step][6])*(start_pul3-instruct[instruct_step][6])));
					float speed_start = distance_start*sqrt((step_acc/100.0)*instruct[3][5]/5000.0)+3;
					if(((int)(speed_start)<instruct_speed)&&((int)(distance_start)<(int)(distance_all/2.0)))
					{
						step_speed = speed_start;
					}

					float distance_end =(sqrt(
							(cur_pulse1-instruct[instruct_step][4])*(cur_pulse1-instruct[instruct_step][4])+
							(cur_pulse2-instruct[instruct_step][5])*(cur_pulse2-instruct[instruct_step][5])+
							(cur_pulse3-instruct[instruct_step][6])*(cur_pulse3-instruct[instruct_step][6])));
					float speed_end = distance_end*sqrt((step_acc/100.0)*instruct[3][5]/5000.0)+3;
					if(((int)(speed_end)<instruct_speed)&&((int)(distance_end)<(int)(distance_all/2.0)))
					{
						step_speed = speed_end;
					}

				}

//				if((abs((int)ik_z-(int)new_z)<1)&&
//						(abs((int)ik_x-(int)new_x)<1)&&
//						(abs((int)ik_y-(int)new_y)<1))
//				{
//					ik_a1 = instruct[instruct_step][4];
//					ik_a2 = instruct[instruct_step][5];
//					ik_a3 = instruct[instruct_step][7];
//
//				}

				instruct[0][2] = (int)step_speed;
				instruct[0][3] = (int)(((step_acc)*instruct[3][5]/100.0));
				step=step+step_speed/255.0;

				if((step1_err!=(int)(step*step1_scale))&&(abs(foc_cut[0])<800)){
					step1_err=(int)(step*step1_scale);
					if(cur_pulse1<(int)ik_a1){
						HAL_GPIO_WritePin(STEP1_DIR_GPIO_Port,STEP1_DIR_Pin,GPIO_PIN_RESET);
						HAL_GPIO_WritePin(STEP1_PUL_GPIO_Port,STEP1_PUL_Pin,GPIO_PIN_RESET);
						cur_pulse1++;

					}
					else if (cur_pulse1>(int)ik_a1){
						HAL_GPIO_WritePin(STEP1_DIR_GPIO_Port,STEP1_DIR_Pin,GPIO_PIN_SET);
						HAL_GPIO_WritePin(STEP1_PUL_GPIO_Port,STEP1_PUL_Pin,GPIO_PIN_RESET);
						cur_pulse1--;

					}

				}

				if((step2_err!=(int)(step*step2_scale))&&(abs(foc_cut[1])<800)){
					step2_err=(int)(step*step2_scale);
					if(cur_pulse2<(int)ik_a2){
						HAL_GPIO_WritePin(STEP2_DIR_GPIO_Port,STEP2_DIR_Pin,GPIO_PIN_RESET);
						HAL_GPIO_WritePin(STEP2_PUL_GPIO_Port,STEP2_PUL_Pin,GPIO_PIN_RESET);
						cur_pulse2++;

					}
					else if (cur_pulse2>(int)ik_a2){
						HAL_GPIO_WritePin(STEP2_DIR_GPIO_Port,STEP2_DIR_Pin,GPIO_PIN_SET);
						HAL_GPIO_WritePin(STEP2_PUL_GPIO_Port,STEP2_PUL_Pin,GPIO_PIN_RESET);
						cur_pulse2--;

					}

				}

				if((step3_err!=(int)(step*step3_scale))&&(abs(foc_cut[2])<800))
				{
					step3_err=(int)(step*step3_scale);
					if(cur_pulse3<(int)(ik_a3-180.0/0.0113924))
					{
						HAL_GPIO_WritePin(STEP3_DIR_GPIO_Port,STEP3_DIR_Pin,GPIO_PIN_SET);
						HAL_GPIO_WritePin(STEP3_PUL_GPIO_Port,STEP3_PUL_Pin,GPIO_PIN_RESET);
						cur_pulse3++;

					}
					else if (cur_pulse3>(int)(ik_a3-180.0/0.0113924))
					{
						HAL_GPIO_WritePin(STEP3_DIR_GPIO_Port,STEP3_DIR_Pin,GPIO_PIN_RESET);
						HAL_GPIO_WritePin(STEP3_PUL_GPIO_Port,STEP3_PUL_Pin,GPIO_PIN_RESET);
						cur_pulse3--;

					}

				}

				if((step4_err!=(int)(step*step4_scale))&&(abs(foc_cut[3])<800))
				{
					step4_err=(int)(step*step4_scale);
//					if(cur_pulse4<(int)(ik_a4))
					if(cur_pulse4<instruct[instruct_step][7])
					{
						step4_is_run = 1;
						HAL_GPIO_WritePin(STEP4_DIR_GPIO_Port,STEP4_DIR_Pin,GPIO_PIN_RESET);
						HAL_GPIO_WritePin(STEP4_PUL_GPIO_Port,STEP4_PUL_Pin,GPIO_PIN_SET);
						cur_pulse4++;
						HAL_GPIO_WritePin(STEP5_DIR_GPIO_Port,STEP5_DIR_Pin,GPIO_PIN_SET);
						HAL_GPIO_WritePin(STEP5_PUL_GPIO_Port,STEP5_PUL_Pin,GPIO_PIN_RESET);

					}
//					else if(cur_pulse4>(int)(ik_a4))
					else if (cur_pulse4>instruct[instruct_step][7])
					{
						step4_is_run = 1;
						HAL_GPIO_WritePin(STEP4_DIR_GPIO_Port,STEP4_DIR_Pin,GPIO_PIN_SET);
						HAL_GPIO_WritePin(STEP4_PUL_GPIO_Port,STEP4_PUL_Pin,GPIO_PIN_SET);
						cur_pulse4--;
						HAL_GPIO_WritePin(STEP5_DIR_GPIO_Port,STEP5_DIR_Pin,GPIO_PIN_RESET);
						HAL_GPIO_WritePin(STEP5_PUL_GPIO_Port,STEP5_PUL_Pin,GPIO_PIN_RESET);

					}

				}else step4_is_run=0;

				if((step5_err!=(int)(step*step5_scale))&&(step4_is_run==0)&&(abs(foc_cut[4])<800)){
					step5_err=(int)(step*step5_scale);
					if(cur_pulse5<instruct[instruct_step][8]){
						HAL_GPIO_WritePin(STEP5_DIR_GPIO_Port,STEP5_DIR_Pin,GPIO_PIN_RESET);
						HAL_GPIO_WritePin(STEP5_PUL_GPIO_Port,STEP5_PUL_Pin,GPIO_PIN_RESET);
						cur_pulse5++;
					}
					else if (cur_pulse5>instruct[instruct_step][8]){
						HAL_GPIO_WritePin(STEP5_DIR_GPIO_Port,STEP5_DIR_Pin,GPIO_PIN_SET);
						HAL_GPIO_WritePin(STEP5_PUL_GPIO_Port,STEP5_PUL_Pin,GPIO_PIN_RESET);
						cur_pulse5--;
					}

				}

				if((step6_err!=(int)(step*step6_scale))&&(abs(foc_cut[5])<800)){
					step6_err=(int)(step*step6_scale);
					if(cur_pulse6<instruct[instruct_step][9]){
						HAL_GPIO_WritePin(STEP6_DIR_GPIO_Port,STEP6_DIR_Pin,GPIO_PIN_SET);
						HAL_GPIO_WritePin(STEP6_PUL_GPIO_Port,STEP6_PUL_Pin,GPIO_PIN_RESET);
						cur_pulse6=cur_pulse6+6;
					}
					else if (cur_pulse6>instruct[instruct_step][9]){
						HAL_GPIO_WritePin(STEP6_DIR_GPIO_Port,STEP6_DIR_Pin,GPIO_PIN_RESET);
						HAL_GPIO_WritePin(STEP6_PUL_GPIO_Port,STEP6_PUL_Pin,GPIO_PIN_RESET);
						cur_pulse6=cur_pulse6-6;
					}
				}

			}

		}else key_flag = 0;

	}

}

/* USER CODE END 4 */

void Error_Handler(void)
{
  __disable_irq();
  while (1)
  {
  }
}

/************************ (C) COPYRIGHT STMicroelectronics *****END OF FILE****/

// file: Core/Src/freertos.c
/* USER CODE BEGIN Header */
/**
  ******************************************************************************
  * File Name          : freertos.c
  * Description        : Code for freertos applications
  ******************************************************************************
  * @attention
  *
  * <h2><center>&copy; Copyright (c) 2021 STMicroelectronics.
  * All rights reserved.</center></h2>
  *
  * This software component is licensed by ST under Ultimate Liberty license
  * SLA0044, the "License"; You may not use this file except in compliance with
  * the License. You may obtain a copy of the License at:
  *                             www.st.com/SLA0044
  *
  ******************************************************************************
  */
/* USER CODE END Header */

#include "FreeRTOS.h"
#include "task.h"
#include "main.h"
#include "cmsis_os.h"

/* USER CODE BEGIN Includes */
#include "adc.h"
#include "dma.h"
#include "tim.h"
#include "usart.h"
#include "gpio.h"
/* USER CODE END Includes */

/* USER CODE BEGIN PD */
#define FLASH_USER_START_ADDR   ADDR_FLASH_SECTOR_5   /* Start @ of user Flash area */
#define FLASH_USER_END_ADDR     ADDR_FLASH_SECTOR_6  +  GetSectorSize(ADDR_FLASH_SECTOR_6) -1 /* End @ of user Flash area : sector start address + sector size -1 */

#define DATA_32                 ((uint32_t)0)

uint32_t FirstSector = 0, NbOfSectors = 0, Address = 0;
uint32_t SectorError = 0;
__IO uint32_t data32 = 0 , MemoryProgramStatus = 0;

static FLASH_EraseInitTypeDef EraseInitStruct;

static uint32_t GetSector(uint32_t Address);
static uint32_t GetSectorSize(uint32_t Sector);

/**
  * @brief  Gets the sector of a given address
  * @param  None
  * @retval The sector of a given address
  */
static uint32_t GetSector(uint32_t Address)
{
  uint32_t sector = 0;

  if((Address < ADDR_FLASH_SECTOR_1) && (Address >= ADDR_FLASH_SECTOR_0))
  {
    sector = FLASH_SECTOR_0;
  }
  else if((Address < ADDR_FLASH_SECTOR_2) && (Address >= ADDR_FLASH_SECTOR_1))
  {
    sector = FLASH_SECTOR_1;
  }
  else if((Address < ADDR_FLASH_SECTOR_3) && (Address >= ADDR_FLASH_SECTOR_2))
  {
    sector = FLASH_SECTOR_2;
  }
  else if((Address < ADDR_FLASH_SECTOR_4) && (Address >= ADDR_FLASH_SECTOR_3))
  {
    sector = FLASH_SECTOR_3;
  }
  else if((Address < ADDR_FLASH_SECTOR_5) && (Address >= ADDR_FLASH_SECTOR_4))
  {
    sector = FLASH_SECTOR_4;
  }
  else if((Address < ADDR_FLASH_SECTOR_6) && (Address >= ADDR_FLASH_SECTOR_5))
  {
    sector = FLASH_SECTOR_5;
  }
  else if((Address < ADDR_FLASH_SECTOR_7) && (Address >= ADDR_FLASH_SECTOR_6))
  {
    sector = FLASH_SECTOR_6;
  }
  else if((Address < ADDR_FLASH_SECTOR_8) && (Address >= ADDR_FLASH_SECTOR_7))
  {
    sector = FLASH_SECTOR_7;
  }
  else if((Address < ADDR_FLASH_SECTOR_9) && (Address >= ADDR_FLASH_SECTOR_8))
  {
    sector = FLASH_SECTOR_8;
  }
  else if((Address < ADDR_FLASH_SECTOR_10) && (Address >= ADDR_FLASH_SECTOR_9))
  {
    sector = FLASH_SECTOR_9;
  }
  else if((Address < ADDR_FLASH_SECTOR_11) && (Address >= ADDR_FLASH_SECTOR_10))
  {
    sector = FLASH_SECTOR_10;
  }
  else /* (Address < FLASH_END_ADDR) && (Address >= ADDR_FLASH_SECTOR_11) */
  {
    sector = FLASH_SECTOR_11;
  }

  return sector;
}

/**
  * @brief  Gets sector Size
  * @param  None
  * @retval The size of a given sector
  */
static uint32_t GetSectorSize(uint32_t Sector)
{
  uint32_t sectorsize = 0x00;

  if((Sector == FLASH_SECTOR_0) || (Sector == FLASH_SECTOR_1) || (Sector == FLASH_SECTOR_2) || (Sector == FLASH_SECTOR_3))
  {
    sectorsize = 16 * 1024;
  }
  else if(Sector == FLASH_SECTOR_4)
  {
    sectorsize = 64 * 1024;
  }
  else
  {
    sectorsize = 128 * 1024;
  }
  return sectorsize;
}

/* USER CODE END PD */

/* USER CODE BEGIN Variables */

uint32_t count=0;
uint16_t adc_filter[11];
uint16_t adc_first[11];
int adc_one[11];
int foc[6];

int foc_cut[6];
int16_t instruct[500][11]=
{{0,0,0,0,0,0,0,0,0,0,0},
{0,0,0,0,0,0,0,0,0,0,0},
{0,0,0,0,0,0,0,0,0,0,0},
{0,0,0,0,0,0,0,0,0,0,0},
{0,0,0,0,0,0,0,0,0,0,0},
{0,0,0,0,0,0,0,0,0,0,0},
{0,0,0,0,0,0,0,0,0,0,0},
{0,0,0,0,0,0,0,0,0,0,0},
{0,0,0,0,0,0,0,0,0,0,0},
{0,0,0,0,0,0,0,0,0,0,0},
{0,0,0x3f,0x3f,0,0,0,0,0,0,0},
{0,0,0x3f,0x3f,500,0,0,0,0,0,0},
{0,0,0x1f,0x3f,600,0,0,0,0,0,0},
{0,0,0x3f,0x3f,600,500,0,0,0,0,0},
{0,0,0x1f,0x3f,600,600,0,0,0,0,0},
{0,0,0x3f,0x3f,600,600,500,0,0,0,0},
{0,0,0x1f,0x3f,600,600,600,0,0,0,0},
{0,0,0x3f,0x3f,0,0,0,0,0,0,0},
{0,0,0x1f,0x3f,0,0,0,0,0,0,0},
{0,0,0x3f,0x3f,0,0,0,0,0,0,0},
{0,0,0x1f,0x3f,0,0,0,0,0,0,0},
{0,0,0x3f,0x3f,0,0,0,0,0,0,0},
{0,0,0x1f,0x3f,0,0,0,0,0,0,0},
{0,0,0x2f,0x3f,0,0,0,0,0,0,0},
{0,0,0x1f,0x3f,0,0,0,0,0,0,0},
{0,0,0x0f,0x3f,0,0,0,0,0,0,0}};//模式，条件|输出，速度，加速度，位置，时间延时

int instruct_step=10;
int total_step =500;
float step=0;
float step_speed=0;
float step_acc=0;
float step_time=0;
char is_start=0;
char is_stop=0;
char is_single_run=0;
char is_record=0;
//电机1参数
int tar_pulse1=0;
int cur_pulse1=0;
int pre_pulse1=0;
int tar_speed1=0;
int cur_speed1=0;
int tar_acc1=0;
int cur_acc1=0;

//电机2参数
int tar_pulse2=0;
int cur_pulse2=0;
int pre_pulse2=0;
int tar_speed2=0;
int cur_speed2=0;
int tar_acc2=0;
int cur_acc2=0;

//电机3参数
int tar_pulse3=0;
int cur_pulse3=0;
int tar_speed3=0;
int cur_speed3=0;
int tar_acc3=0;
int cur_acc3=0;

//电机4参数
int tar_pulse4=0;
int cur_pulse4=0;
int tar_speed4=0;
int cur_speed4=0;
int tar_acc4=0;
int cur_acc4=0;

//电机5参数
int tar_pulse5=0;
int cur_pulse5=0;
int tar_speed5=0;
int cur_speed5=0;
int tar_acc5=0;
int cur_acc5=0;

//电机6参数
int tar_pulse6=0;
int cur_pulse6=0;
int tar_speed6=0;
int cur_speed6=0;
int tar_acc6=0;
int cur_acc6=0;

unsigned short CRC16_Modbus ( unsigned char *pdata, int len)
{
	unsigned short crc=0xFFFF;
	int i, j;
	for ( j=0; j<len;j++)
	{
		crc=crc^pdata[j];
		for ( i=0; i<8; i++)
		{
			if( ( crc&0x0001) >0)
			{
				crc=crc>>1;
				crc=crc^ 0xa001;
			}
			else
				crc=crc>>1;
		}
	}
	return crc;
}

/* USER CODE END Variables */
osThreadId defaultTaskHandle;
osThreadId LedTaskHandle;
osThreadId SendTaskHandle;
osThreadId RobotTaskHandle;
osThreadId DemoTaskHandle;
osThreadId TestTaskHandle;
osThreadId ModbusTaskHandle;

void StartDefaultTask(void const * argument);
void StartLedTask(void const * argument);
void StartSendTask(void const * argument);
void StartRobotTask(void const * argument);
void StartDemoTask(void const * argument);
void StartTestTask(void const * argument);
void StartModbusTask(void const * argument);

void MX_FREERTOS_Init(void); /* (MISRA C 2004 rule 8.1) */

/* GetIdleTaskMemory prototype (linked to static allocation support) */
void vApplicationGetIdleTaskMemory( StaticTask_t **ppxIdleTaskTCBBuffer, StackType_t **ppxIdleTaskStackBuffer, uint32_t *pulIdleTaskStackSize );

/* USER CODE BEGIN GET_IDLE_TASK_MEMORY */
static StaticTask_t xIdleTaskTCBBuffer;
static StackType_t xIdleStack[configMINIMAL_STACK_SIZE];

void vApplicationGetIdleTaskMemory( StaticTask_t **ppxIdleTaskTCBBuffer, StackType_t **ppxIdleTaskStackBuffer, uint32_t *pulIdleTaskStackSize )
{
  *ppxIdleTaskTCBBuffer = &xIdleTaskTCBBuffer;
  *ppxIdleTaskStackBuffer = &xIdleStack[0];
  *pulIdleTaskStackSize = configMINIMAL_STACK_SIZE;
  /* place for user code */
}
/* USER CODE END GET_IDLE_TASK_MEMORY */

void MX_FREERTOS_Init(void) {

  /* Create the thread(s) */
  /* definition and creation of defaultTask */
  osThreadDef(defaultTask, StartDefaultTask, osPriorityNormal, 0, 128);
  defaultTaskHandle = osThreadCreate(osThread(defaultTask), NULL);

  /* definition and creation of LedTask */
  osThreadDef(LedTask, StartLedTask, osPriorityNormal, 0, 128);
  LedTaskHandle = osThreadCreate(osThread(LedTask), NULL);

  /* definition and creation of SendTask */
  osThreadDef(SendTask, StartSendTask, osPriorityNormal, 0, 512);
  SendTaskHandle = osThreadCreate(osThread(SendTask), NULL);

  /* definition and creation of RobotTask */
  osThreadDef(RobotTask, StartRobotTask, osPriorityNormal, 0, 256);
  RobotTaskHandle = osThreadCreate(osThread(RobotTask), NULL);

  /* definition and creation of DemoTask */
  osThreadDef(DemoTask, StartDemoTask, osPriorityNormal, 0, 128);
  DemoTaskHandle = osThreadCreate(osThread(DemoTask), NULL);

  /* definition and creation of TestTask */
  osThreadDef(TestTask, StartTestTask, osPriorityIdle, 0, 128);
  TestTaskHandle = osThreadCreate(osThread(TestTask), NULL);

  /* definition and creation of ModbusTask */
  osThreadDef(ModbusTask, StartModbusTask, osPriorityNormal, 0, 512);
  ModbusTaskHandle = osThreadCreate(osThread(ModbusTask), NULL);

}

void StartDefaultTask(void const * argument)
{
  for(;;)
  {
    osDelay(1);
  }
}

void StartLedTask(void const * argument)
{
  /* USER CODE BEGIN StartLedTask */

  /* Infinite loop */
  for(;;)
  {
  	HAL_GPIO_TogglePin(LED0_GPIO_Port, LED0_Pin);
//  	HAL_GPIO_TogglePin(STEP4_PUL_GPIO_Port, STEP4_PUL_Pin);
    osDelay(100);
  }
  /* USER CODE END StartLedTask */
}

void StartSendTask(void const * argument)
{
  /* USER CODE BEGIN StartSendTask */
  /* Infinite loop */
  for(;;)
  {

  	instruct[0][4] = cur_pulse1*0.6338;
  	instruct[0][5] = cur_pulse2*0.67164;
  	instruct[0][6] = cur_pulse3*1.13924;
  	instruct[0][7] = cur_pulse4*1.56673;
  	instruct[0][8] = cur_pulse5*2.45108;
  	instruct[0][9] = cur_pulse6;

  	instruct[2][4] = (instruct[2][2]+10)*11;
  	instruct_step = instruct[2][2]+10;
  	total_step = instruct[2][1];
    osDelay(10);
  }
  /* USER CODE END StartSendTask */
}

void StartRobotTask(void const * argument)
{
  /* USER CODE BEGIN StartRobotTask */
	osDelay(1000);

	Address = FLASH_USER_START_ADDR;
	for(int j=11;j<(500*11);j++)
	{
		instruct[j/11][j%11] = (*(__IO int16_t*)Address);
		Address = Address + 2;
	}
	instruct[1][0]=0;
	instruct[1][1]=0;
	instruct[1][2]=0;
	instruct[1][3]=0;
	instruct[1][4]=0;
	instruct[1][5]=0;
	instruct[1][6]=0;
	instruct[1][7]=0;
	instruct[1][8]=0;
	instruct[1][9]=0;
	instruct[1][10]=0;
	instruct[2][0]=0;
	instruct[2][2]=0;

	is_start = 0;
  /* Infinite loop */
  for(;;)
  {
  	if(is_start==0)
  	{
  		if(instruct[0][0]==0)
  		{
  			for(int i=0;i<6;i++)
  			{
  				if(foc_cut[i]>-10)foc_cut[i]-=10;
  				if(foc_cut[i]<10)foc_cut[i]+=10;
  			}
  		}
  		else if(instruct[0][0]==1&&foc_cut[0]<3000)foc_cut[0]++;
  		else if(instruct[0][0]==2&&foc_cut[0]>-3000)foc_cut[0]--;
  		else if(instruct[0][0]==4&&foc_cut[1]<3000)foc_cut[1]++;
  		else if(instruct[0][0]==8&&foc_cut[1]>-3000)foc_cut[1]--;
  		else if(instruct[0][0]==16&&foc_cut[2]<3000)foc_cut[2]++;
  		else if(instruct[0][0]==32&&foc_cut[2]>-3000)foc_cut[2]--;
  		else if(instruct[0][0]==64&&foc_cut[3]<3000)foc_cut[3]++;
  		else if(instruct[0][0]==128&&foc_cut[3]>-3000)foc_cut[3]--;
  		else if(instruct[0][0]==256&&foc_cut[4]<3000)foc_cut[4]++;
  		else if(instruct[0][0]==512&&foc_cut[4]>-3000)foc_cut[4]--;
  		else if(instruct[0][0]==1024&&foc_cut[5]<3000)foc_cut[5]++;
  		else if(instruct[0][0]==2048&&foc_cut[5]>-3000)foc_cut[5]--;

  		if(instruct[2][0]==0)
  		{
  			is_single_run = 0;
  		}
  		else if(instruct[2][0]==1)
  		{

  			instruct[instruct_step][4] = cur_pulse1;
  			instruct[instruct_step][5] = cur_pulse2;
  			instruct[instruct_step][6] = cur_pulse3;
  			instruct[instruct_step][7] = cur_pulse4;
  			instruct[instruct_step][8] = cur_pulse5;
  			instruct[instruct_step][9] = cur_pulse6;
  		}
  		else if(instruct[2][0]==2)
  		{
  			is_single_run = 1;
  		}

  		else if(instruct[2][0]==4)
  		{
  		  /* Unlock the Flash to enable the flash control register access *************/
  		  HAL_FLASH_Unlock();

  		  /* Erase the user Flash area
  		    (area defined by FLASH_USER_START_ADDR and FLASH_USER_END_ADDR) ***********/

  		  /* Get the 1st sector to erase */
  		  FirstSector = GetSector(FLASH_USER_START_ADDR);
  		  /* Get the number of sector to erase from 1st sector*/
  		  NbOfSectors = GetSector(FLASH_USER_END_ADDR) - FirstSector + 1;

  		  /* Fill EraseInit structure*/
  		  EraseInitStruct.TypeErase = FLASH_TYPEERASE_SECTORS;
  		  EraseInitStruct.VoltageRange = FLASH_VOLTAGE_RANGE_3;
  		  EraseInitStruct.Sector = FirstSector;
  		  EraseInitStruct.NbSectors = NbOfSectors;
  		  if(HAL_FLASHEx_Erase(&EraseInitStruct, &SectorError) != HAL_OK)
  		  {
  		    while (1)
  		    {
  		    	osDelay(1000);
  		    	HAL_GPIO_TogglePin(LED0_GPIO_Port, LED0_Pin);
  		    }
  		  }

  		  /* Note: If an erase operation in Flash memory also concerns data in the data or instruction cache,
  		      you have to make sure that these data are rewritten before they are accessed during code
  		      execution. If this cannot be done safely, it is recommended to flush the caches by setting the
  		      DCRST and ICRST bits in the FLASH_CR register. */
  		   __HAL_FLASH_DATA_CACHE_DISABLE();
  		   __HAL_FLASH_INSTRUCTION_CACHE_DISABLE();

  		   __HAL_FLASH_DATA_CACHE_RESET();
  		   __HAL_FLASH_INSTRUCTION_CACHE_RESET();

  		   __HAL_FLASH_INSTRUCTION_CACHE_ENABLE();
  		   __HAL_FLASH_DATA_CACHE_ENABLE();

  		   /* Program the user Flash area word by word
  		     (area defined by FLASH_USER_START_ADDR and FLASH_USER_END_ADDR) ***********/

  		   Address = FLASH_USER_START_ADDR;
  		   int instruct_addr = 11;
  		   int instruct_data = 0;
  		   while (Address < FLASH_USER_END_ADDR)
  		   {
  		  	 if(instruct_addr<(11*500))
  		  	 {
  		  		 instruct_data = instruct[instruct_addr/11][instruct_addr%11];
  		  	 }
  		  	 else instruct_data = 0;

  		     if (HAL_FLASH_Program(FLASH_TYPEPROGRAM_HALFWORD, Address, instruct_data) == HAL_OK)
  		     {
  		    	 instruct_addr++;
  		       Address = Address + 2;
  		     }
  		     else
  		     {
  		       /* Error occurred while writing data in Flash memory.
  		          User can add here some code to deal with this error */
  		       while (1)
  		       {
    		       	osDelay(500);
    		       	HAL_GPIO_TogglePin(LED0_GPIO_Port, LED0_Pin);
  		       }
  		     }
  		   }

  		   /* Lock the Flash to disable the flash control register access (recommended
  		      to protect the FLASH memory against possible unwanted operation) *********/
  		   HAL_FLASH_Lock();
  		}

  		else if(instruct[2][0]==8)
  		{
  		  /* Unlock the Flash to enable the flash control register access *************/
  		  HAL_FLASH_Unlock();

  		  /* Erase the user Flash area
  		    (area defined by FLASH_USER_START_ADDR and FLASH_USER_END_ADDR) ***********/

  		  /* Get the 1st sector to erase */
  		  FirstSector = GetSector(FLASH_USER_START_ADDR);
  		  /* Get the number of sector to erase from 1st sector*/
  		  NbOfSectors = GetSector(FLASH_USER_END_ADDR) - FirstSector + 1;

  		  /* Fill EraseInit structure*/
  		  EraseInitStruct.TypeErase = FLASH_TYPEERASE_SECTORS;
  		  EraseInitStruct.VoltageRange = FLASH_VOLTAGE_RANGE_3;
  		  EraseInitStruct.Sector = FirstSector;
  		  EraseInitStruct.NbSectors = NbOfSectors;
  		  if(HAL_FLASHEx_Erase(&EraseInitStruct, &SectorError) != HAL_OK)
  		  {
  		    while (1)
  		    {
  		    	osDelay(1000);
  		    	HAL_GPIO_TogglePin(LED0_GPIO_Port, LED0_Pin);
  		    }
  		  }

  		  /* Note: If an erase operation in Flash memory also concerns data in the data or instruction cache,
  		      you have to make sure that these data are rewritten before they are accessed during code
  		      execution. If this cannot be done safely, it is recommended to flush the caches by setting the
  		      DCRST and ICRST bits in the FLASH_CR register. */
  		   __HAL_FLASH_DATA_CACHE_DISABLE();
  		   __HAL_FLASH_INSTRUCTION_CACHE_DISABLE();

  		   __HAL_FLASH_DATA_CACHE_RESET();
  		   __HAL_FLASH_INSTRUCTION_CACHE_RESET();

  		   __HAL_FLASH_INSTRUCTION_CACHE_ENABLE();
  		   __HAL_FLASH_DATA_CACHE_ENABLE();

  		   /* Program the user Flash area word by word
  		     (area defined by FLASH_USER_START_ADDR and FLASH_USER_END_ADDR) ***********/

  		   Address = FLASH_USER_START_ADDR;
  		   while (Address < FLASH_USER_END_ADDR)
  		   {
  		     if (HAL_FLASH_Program(FLASH_TYPEPROGRAM_HALFWORD, Address, 0) == HAL_OK)
  		     {
  		       Address = Address + 2;
  		     }
  		     else
  		     {
  		       /* Error occurred while writing data in Flash memory.
  		          User can add here some code to deal with this error */
  		       while (1)
  		       {
    		       	osDelay(500);
    		       	HAL_GPIO_TogglePin(LED0_GPIO_Port, LED0_Pin);
  		       }
  		     }
  		   }

  		   /* Lock the Flash to disable the flash control register access (recommended
  		      to protect the FLASH memory against possible unwanted operation) *********/
  		   HAL_FLASH_Lock();
  		}

  	}

		if(instruct[3][0]&0x01)
		{
			is_start = 1;
		}
		else is_start = 0;

		if(instruct[3][0]&0x02)
		{
			is_stop = 1;
			is_start = 0;
		}
		else is_stop = 0;

    osDelay(1);
  }
  /* USER CODE END StartRobotTask */
}

void StartDemoTask(void const * argument)
{
  for(;;)
  {
    osDelay(1);
  }
}

void StartTestTask(void const * argument)
{
  /* USER CODE BEGIN StartTestTask */
  /* Infinite loop */
  for(;;)
  {
  	HAL_UART_Receive_DMA(&huart2, rx_data, rx_bufSize);
    osDelay(1000);
  }
  /* USER CODE END StartTestTask */
}

void StartModbusTask(void const * argument)
{
  /* USER CODE BEGIN StartModbusTask */
	uint8_t rx_modbus[rx_bufSize];
	uint8_t tx_modbus[rx_bufSize];
	uint16_t start_count = 0;
	uint16_t end_count = 0;
	uint8_t flag = 0;
	uint16_t crc = 0;
	int time_out = 25;
  /* Infinite loop */
  for(;;)
  {
  	rx_Count = rx_bufSize - __HAL_DMA_GET_COUNTER(&hdma_usart2_rx);
  	if(flag==1 && rx_Count==end_count)
  	{
  		flag=0;
  		int len=0;
  		for(;start_count!=end_count;)
  		{
  			rx_modbus[len++] = rx_data[start_count++];
  			if(start_count>=rx_bufSize)start_count = 0;
  		}

  		crc=CRC16_Modbus(rx_modbus,len-2);
  		if(BYTE0(crc)==rx_modbus[len-2]&&BYTE1(crc)==rx_modbus[len-1])
  		{
  			time_out=25;
  			if(rx_modbus[1]==0x03)
  			{
					uint16_t tx_len=0;
					uint16_t adrr=0;
					tx_modbus[tx_len++] = rx_modbus[0];
					tx_modbus[tx_len++] = rx_modbus[1];
					adrr = rx_modbus[2]*256+rx_modbus[3];
					tx_modbus[tx_len++] = rx_modbus[5]*2;
					for(int i=0; i<rx_modbus[5];i++,adrr++)
					{
						tx_modbus[tx_len++] = BYTE1(instruct[(adrr)/11][adrr%11]);
						tx_modbus[tx_len++] = BYTE0(instruct[(adrr)/11][adrr%11]);
					}
					crc=CRC16_Modbus(tx_modbus,tx_len);
					tx_modbus[tx_len++] = BYTE0(crc);
					tx_modbus[tx_len++] = BYTE1(crc);

					HAL_UART_Transmit_DMA(&huart2, tx_modbus, tx_len);
  			}
  			else if(rx_modbus[1]==0x04)
  			{
					uint16_t tx_len=0;
					uint16_t adrr=0;
					tx_modbus[tx_len++] = rx_modbus[0];
					tx_modbus[tx_len++] = rx_modbus[1];
					adrr = rx_modbus[2]*256+rx_modbus[3];
					tx_modbus[tx_len++] = rx_modbus[5]*2;
					for(int i=0; i<rx_modbus[5];i++,adrr++)
					{
						tx_modbus[tx_len++] = BYTE1(adc_data[adrr]);
						tx_modbus[tx_len++] = BYTE0(adc_data[adrr]);
					}
					crc=CRC16_Modbus(tx_modbus,tx_len);
					tx_modbus[tx_len++] = BYTE0(crc);
					tx_modbus[tx_len++] = BYTE1(crc);
					HAL_UART_Transmit_DMA(&huart2, tx_modbus, tx_len);
  			}
  			else if(rx_modbus[1]==0x10)
  			{
					uint16_t tx_len=0;
					uint16_t adrr=0;
					adrr = rx_modbus[2]*256+rx_modbus[3];
					for(int i=0;i<rx_modbus[6];i+=2,adrr++)
					{
						instruct[(adrr)/11][adrr%11] = rx_modbus[7+i]*256+rx_modbus[8+i];
					}
					tx_modbus[tx_len++] = rx_modbus[0];
					tx_modbus[tx_len++] = rx_modbus[1];
					tx_modbus[tx_len++] = rx_modbus[2];
					tx_modbus[tx_len++] = rx_modbus[3];
					tx_modbus[tx_len++] = rx_modbus[4];
					tx_modbus[tx_len++] = rx_modbus[5];
					crc=CRC16_Modbus(tx_modbus,tx_len);
					tx_modbus[tx_len++] = BYTE0(crc);
					tx_modbus[tx_len++] = BYTE1(crc);
					HAL_UART_Transmit_DMA(&huart2, tx_modbus, tx_len);
  			}
  			else if(rx_modbus[1]==0x06)
  			{
					uint16_t adrr=0;
					adrr = rx_modbus[2]*256+rx_modbus[3];
					instruct[(adrr)/11][adrr%11] = rx_modbus[4]*256+rx_modbus[5];
					HAL_UART_Transmit_DMA(&huart2, rx_modbus, 8);
  			}

  		}

  	}
  	if(rx_Count!=end_count)//正在接收数据
  	{
  		end_count = rx_Count;
  		flag = 1;
  	}
  	else//空闲
  	{
  		time_out--;
  		if(time_out<0)//通信断开
  		{
  			time_out=0;
  			instruct[0][0]=0;
  		}
  	}

    osDelay(2);
  }
  /* USER CODE END StartModbusTask */
}

/************************ (C) COPYRIGHT STMicroelectronics *****END OF FILE****/
